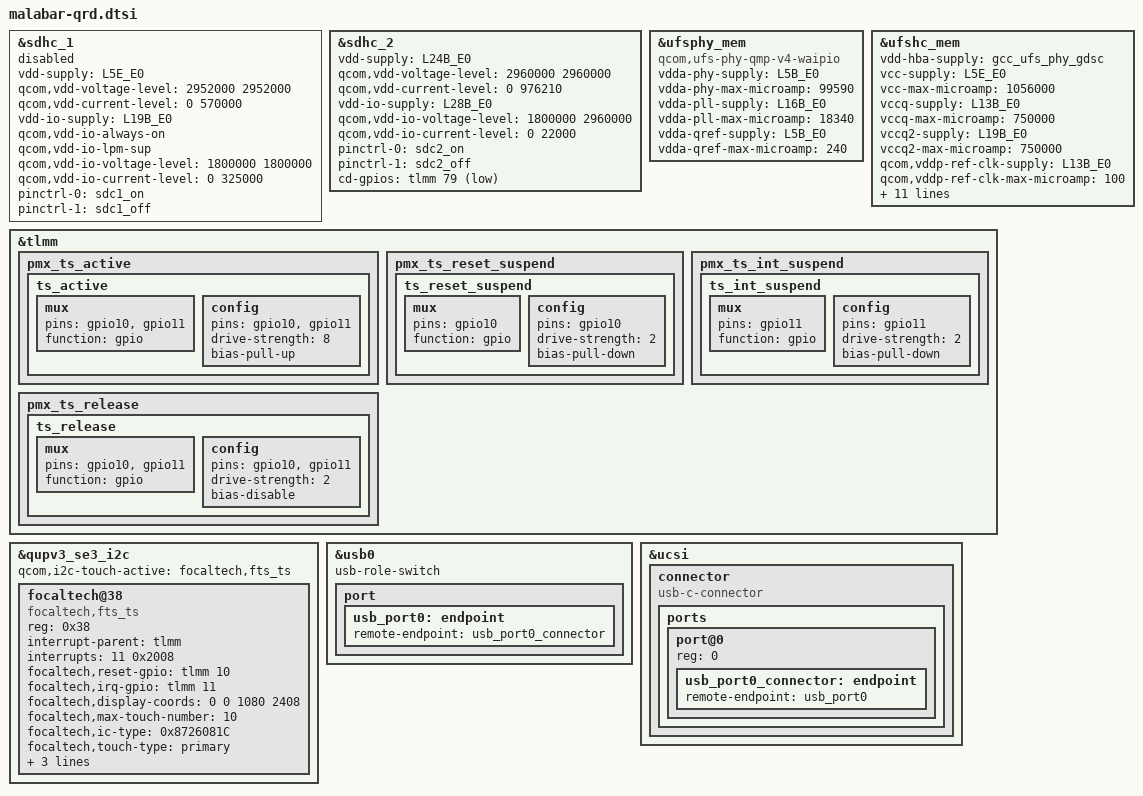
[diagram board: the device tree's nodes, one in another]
// SPDX-License-Identifier: BSD-3-Clause
/*
 * Copyright (c) Qualcomm Technologies, Inc. and/or its subsidiaries.
 */

#include "malabar-pmic-overlay.dtsi"
#include "malabar-thermal-overlay.dtsi"
#include <dt-bindings/gpio/gpio.h>

&sdhc_1 {
	vdd-supply = <&L5E_E0>;
	qcom,vdd-voltage-level = <2952000 2952000>;
	qcom,vdd-current-level = <0 570000>;

	vdd-io-supply = <&L19B_E0>;
	qcom,vdd-io-always-on;
	qcom,vdd-io-lpm-sup;
	qcom,vdd-io-voltage-level = <1800000 1800000>;
	qcom,vdd-io-current-level = <0 325000>;

	pinctrl-names = "default", "sleep";
	pinctrl-0 = <&sdc1_on>;
	pinctrl-1 = <&sdc1_off>;

	status = "disabled";
};

&sdhc_2 {
	vdd-supply = <&L24B_E0>;
	qcom,vdd-voltage-level = <2960000 2960000>;
	qcom,vdd-current-level = <0 976210>;

	vdd-io-supply = <&L28B_E0>;
	qcom,vdd-io-voltage-level = <1800000 2960000>;
	qcom,vdd-io-current-level = <0 22000>;

	pinctrl-names = "default", "sleep";
	pinctrl-0 = <&sdc2_on>;
	pinctrl-1 = <&sdc2_off>;

	cd-gpios = <&tlmm 79 GPIO_ACTIVE_LOW>;

	status = "ok";
};

&ufsphy_mem {
	compatible = "qcom,ufs-phy-qmp-v4-waipio";

	/* VDDA_UFS_CORE */
	vdda-phy-supply = <&L5B_E0>;
	vdda-phy-max-microamp = <99590>;

	/* VDDA_UFS_0_1P2 */
	vdda-pll-supply = <&L16B_E0>;
	vdda-pll-max-microamp = <18340>;

	/* Qref power supply, Refer Qref diagram */
	vdda-qref-supply = <&L5B_E0>;
	vdda-qref-max-microamp = <240>;

	status = "ok";
};

&ufshc_mem {
	vdd-hba-supply = <&gcc_ufs_phy_gdsc>;

	vcc-supply = <&L5E_E0>;
	vcc-max-microamp = <1056000>;

	vccq-supply = <&L13B_E0>;
	vccq-max-microamp = <750000>;

	vccq2-supply = <&L19B_E0>;
	vccq2-max-microamp = <750000>;

	/* VDD_PX10 is voted for the ufs_reset_n */
	qcom,vddp-ref-clk-supply = <&L13B_E0>;
	qcom,vddp-ref-clk-max-microamp = <100>;

	qcom,vccq-proxy-vote-supply = <&L13B_E0>;
	qcom,vccq-proxy-vote-max-microamp = <750000>;

	qcom,vccq2-proxy-vote-supply = <&L19B_E0>;
	qcom,vccq2-proxy-vote-max-microamp = <750000>;

	qcom,vccq-parent-supply = <&S8B_E0>;
	qcom,vccq-parent-max-microamp = <210000>;

	qcom,vccq2-parent-supply = <&S9B_E0>;
	qcom,vccq2-parent-max-microamp = <210000>;

	ufs-dev-types = <2>;
	nvmem-cells = <&ufs_dev>;
	nvmem-cell-names = "ufs_dev";
	status = "ok";
};

#include "malabar-pmiv010x-smb1355.dtsi"

&tlmm {
	pmx_ts_active {
		ts_active: ts_active {
			mux {
				pins = "gpio10", "gpio11";
				function = "gpio";
			};

			config {
				pins = "gpio10", "gpio11";
				drive-strength = <8>;
				bias-pull-up;
			};
		};
	};

	pmx_ts_reset_suspend {
		ts_reset_suspend: ts_reset_suspend {
			mux {
				pins = "gpio10";
				function = "gpio";
			};

			config {
				pins = "gpio10";
				drive-strength = <2>;
				bias-pull-down;
			};
		};
	};

	pmx_ts_int_suspend {
		ts_int_suspend: ts_int_suspend {
			mux {
				pins = "gpio11";
				function = "gpio";
			};

			config {
				pins = "gpio11";
				drive-strength = <2>;
				bias-pull-down;
			};
		};
	};

	pmx_ts_release {
		ts_release: ts_release {
			mux {
				pins = "gpio10", "gpio11";
				function = "gpio";
			};

			config {
				pins = "gpio10", "gpio11";
				drive-strength = <2>;
				bias-disable;
			};
		};
	};
};

&qupv3_se3_i2c {
	#address-cells = <1>;
	#size-cells = <0>;

	status = "okay";
	qcom,i2c-touch-active = "focaltech,fts_ts";

	focaltech@38 {
		compatible = "focaltech,fts_ts";
		reg = <0x38>;

		interrupt-parent = <&tlmm>;
		interrupts = <11 0x2008>;
		focaltech,reset-gpio = <&tlmm 10 0x00>;
		focaltech,irq-gpio = <&tlmm 11 0x2008>;
		focaltech,display-coords = <0 0 1080 2408>;
		focaltech,max-touch-number = <10>;
		focaltech,ic-type = <0x8726081C>;
		focaltech,touch-type = "primary";

		pinctrl-names = "pmx_ts_active","pmx_ts_suspend","pmx_ts_release";
		pinctrl-0 = <&ts_active>;
		pinctrl-1 = <&ts_int_suspend &ts_reset_suspend>;
		pinctrl-2 = <&ts_release>;
	};
};

&usb0 {
	usb-role-switch;

	port {
		usb_port0: endpoint {
			remote-endpoint = <&usb_port0_connector>;
		};
	};
};

&ucsi {
	connector {
		compatible = "usb-c-connector";

		ports {
			#address-cells = <1>;
			#size-cells = <0>;

			port@0 {
				reg = <0>;

				usb_port0_connector: endpoint {
					remote-endpoint = <&usb_port0>;
				};
			};
		};
	};
};

